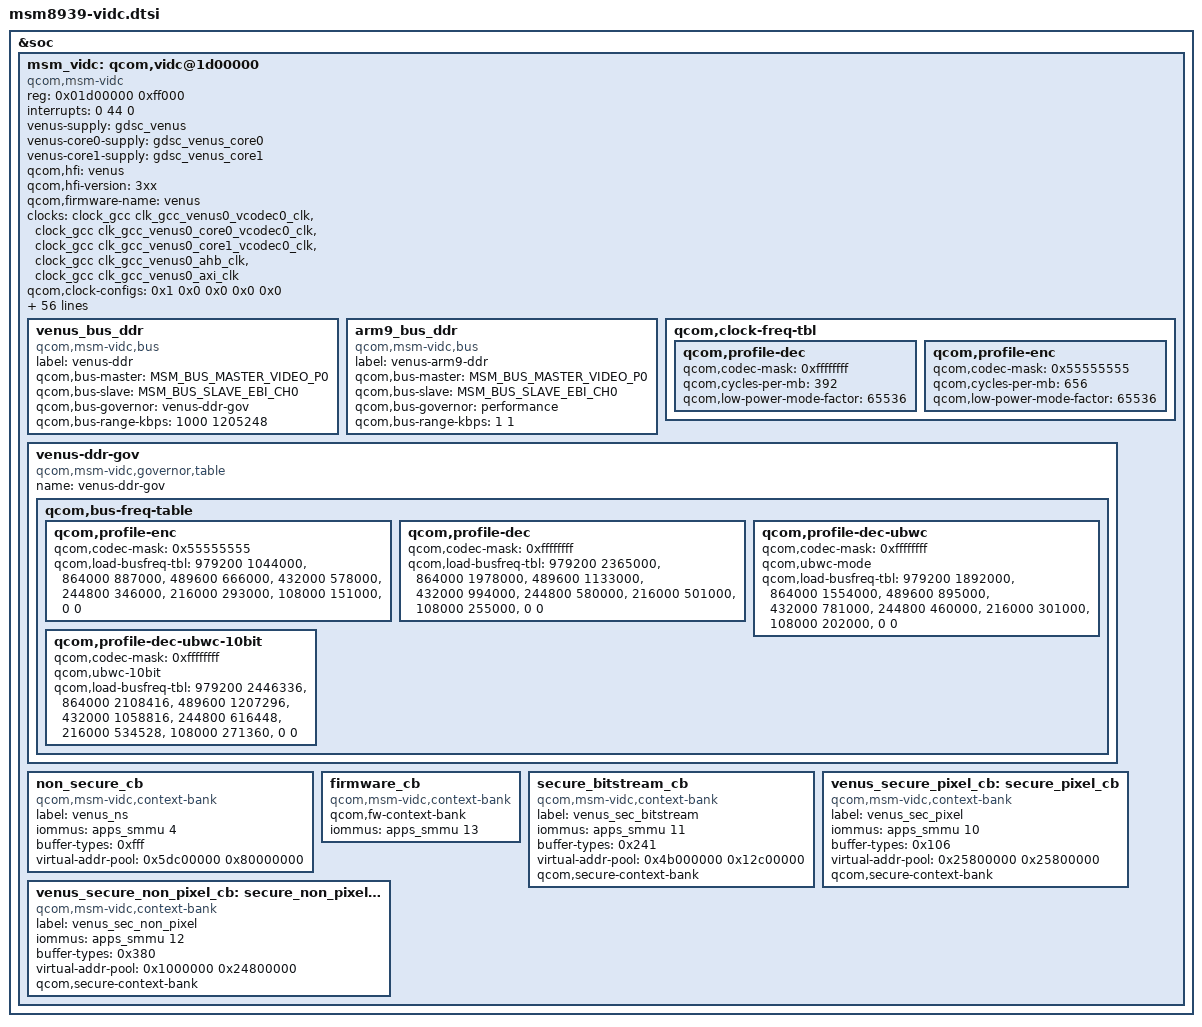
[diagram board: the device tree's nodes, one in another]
/* Copyright (c) 2017, The Linux Foundation. All rights reserved.
 *
 * This program is free software; you can redistribute it and/or modify
 * it under the terms of the GNU General Public License version 2 and
 * only version 2 as published by the Free Software Foundation.
 *
 * This program is distributed in the hope that it will be useful,
 * but WITHOUT ANY WARRANTY; without even the implied warranty of
 * MERCHANTABILITY or FITNESS FOR A PARTICULAR PURPOSE.  See the
 * GNU General Public License for more details.
 */

#include <dt-bindings/interrupt-controller/arm-gic.h>

&soc {
	msm_vidc: qcom,vidc@1d00000 {
		compatible = "qcom,msm-vidc";
		reg = <0x01d00000 0xff000>;
		interrupts = <0 44 0>;
		
		venus-supply = <&gdsc_venus>;
		venus-core0-supply = <&gdsc_venus_core0>;
		venus-core1-supply = <&gdsc_venus_core1>;

		qcom,hfi = "venus";
		qcom,hfi-version = "3xx";
		qcom,firmware-name = "venus";

		clocks = <&clock_gcc clk_gcc_venus0_vcodec0_clk>,
			<&clock_gcc clk_gcc_venus0_core0_vcodec0_clk>,
			<&clock_gcc clk_gcc_venus0_core1_vcodec0_clk>,
			<&clock_gcc clk_gcc_venus0_ahb_clk>,
			<&clock_gcc clk_gcc_venus0_axi_clk>;
		clock-names = "core_clk", "core0_clk", "core1_clk", "iface_clk", "bus_clk";

		qcom,clock-configs = <0x1 0x0 0x0 0x0 0x0>;
		qcom,allowed-clock-rates = <266670000 200000000 133330000>;
		qcom,slave-side-cp;
		qcom,sw-power-collapse;
		qcom,reset-clock-control;
		qcom,regulator-scaling;

		qcom,max-hw-load = <1011840>; /* 3840 x 2176 @ 30 fps + 3840 x 2176 @ 1 fps */
		qcom,dcvs-min-load = <734400>; /* 1920 x 1088 @ 90fps */
		qcom,dcvs-min-mbperframe = <32400>; /* 3840 x 2160 */

		qcom,load-freq-tbl =
			<979200 466000000 0x55555555>, /* TURBO, UHD30E   */
			<979200 400000000 0xffffffff>, /* NOM+ , UHD30D   */
			<734400 360000000 0xffffffff>, /* NOM  , 1080p90D */
			<734400 400000000 0x55555555>, /* NOM+ , 1080p90E */
			<489600 228570000 0xffffffff>, /* SVS  , 1080p60D */
			<489600 466000000 0x55555555>, /* TURBO, 1080p60E */
			<432000 228570000 0xffffffff>, /* SVS  , 720p120D */
			<432000 400000000 0x55555555>, /* NOM+ , 720p120E */
			<244800 133333333 0xffffffff>, /* SVS- , 1080p30D */
			<244800 228570000 0x55555555>, /* SVS  , 1080p30E */
			<216000 100000000 0xffffffff>, /* SVS- , 720p60D  */
			<216000 228570000 0x55555555>, /* SVS  , 720p60E  */
			<108000 80000000 0xffffffff>,  /* SVS--, 720p30D  */
			<108000 100000000 0x55555555>, /* SVS- , 720p30E  */
			<36000 72727200 0xffffffff>,   /* SVS--, 480p30D  */
			<36000 80000000 0x55555555>;   /* SVS--, 480p30E  */

		qcom,dcvs-tbl =
			/* Dec UHD@30 H.264, HEVC, VP8, VP9 - NOM to NOM+*/
			<816000 816000 979200 0x3f00000c>,

			/* Enc UHD@30 H.264/HEVC Turbo to Nom+ */
			<897600 821100 979200 0x4000004>,

			/* Enc True4K@24 H.264/HEVC Nom to Nom+ */
			<816000 720000 835584 0x4000004>;

		qcom,dcvs-limit =
			<32400 24>, /* Encoder UHD */
			<32400 24>; /* Decoder UHD */

		qcom,qdss-presets =
			<0x6025000 0x1000>,
			<0x6026000 0x1000>,
			<0x6021000 0x1000>,
			<0x6002000 0x1000>,
			<0x9180000 0x1000>,
			<0x9181000 0x1000>;

		qcom,reg-presets =
			<0xE0020 0x05555556>,
			<0xE0024 0x05555556>,
			<0x80124 0x00000003>;

		qcom,clock-voltage-tbl =
			<72727200 RPM_SMD_REGULATOR_LEVEL_SVS>,
			<80000000 RPM_SMD_REGULATOR_LEVEL_SVS>,
			<100000000 RPM_SMD_REGULATOR_LEVEL_SVS>,
			<133333333 RPM_SMD_REGULATOR_LEVEL_SVS>,
			<228570000 RPM_SMD_REGULATOR_LEVEL_SVS>,
			<310667000 RPM_SMD_REGULATOR_LEVEL_SVS_PLUS>,
			<360000000 RPM_SMD_REGULATOR_LEVEL_NOM>,
			<400000000 RPM_SMD_REGULATOR_LEVEL_NOM_PLUS>,
			<466000000 RPM_SMD_REGULATOR_LEVEL_TURBO>;

		qcom,vp9d-clock-voltage-tbl =
			<72727200 RPM_SMD_REGULATOR_LEVEL_SVS>,
			<80000000 RPM_SMD_REGULATOR_LEVEL_SVS>,
			<100000000 RPM_SMD_REGULATOR_LEVEL_SVS>,
			<133333333 RPM_SMD_REGULATOR_LEVEL_SVS>,
			<228570000 RPM_SMD_REGULATOR_LEVEL_SVS_PLUS>,
			<310667000 RPM_SMD_REGULATOR_LEVEL_NOM>,
			<360000000 RPM_SMD_REGULATOR_LEVEL_NOM_PLUS>,
			<400000000 RPM_SMD_REGULATOR_LEVEL_TURBO>;

		/* VIDC buses */
		venus_bus_ddr {
			compatible = "qcom,msm-vidc,bus";
			label = "venus-ddr";
			qcom,bus-master = <MSM_BUS_MASTER_VIDEO_P0>;
			qcom,bus-slave = <MSM_BUS_SLAVE_EBI_CH0>;
			qcom,bus-governor = "venus-ddr-gov";
			qcom,bus-range-kbps = <1000 1205248>;
		};

		arm9_bus_ddr {
			compatible = "qcom,msm-vidc,bus";
			label = "venus-arm9-ddr";
			qcom,bus-master = <MSM_BUS_MASTER_VIDEO_P0>;
			qcom,bus-slave = <MSM_BUS_SLAVE_EBI_CH0>;
			qcom,bus-governor = "performance";
			qcom,bus-range-kbps = <1 1>;
		};

		qcom,clock-freq-tbl {
			qcom,profile-dec {
				qcom,codec-mask = <0xffffffff>;
				qcom,cycles-per-mb = <392>;
				qcom,low-power-mode-factor = <65536>;
			};
			qcom,profile-enc {
				qcom,codec-mask = <0x55555555>;
				qcom,cycles-per-mb = <656>;
				qcom,low-power-mode-factor = <65536>;
			};
		};

		/* Bus governor tables */
		venus-ddr-gov {
			compatible = "qcom,msm-vidc,governor,table";
			name = "venus-ddr-gov";
			status = "ok";
			qcom,bus-freq-table {
				qcom,profile-enc {
					/* Codec mask for "all encoders" */
					qcom,codec-mask = <0x55555555>;
					qcom,load-busfreq-tbl =
						<979200 1044000>,  /* UHD30E     */
						<864000 887000>,   /* 720p240LPE */
						<489600 666000>,   /* 1080p60E   */
						<432000 578000>,   /* 720p120E   */
						<244800 346000>,   /* 1080p30E   */
						<216000 293000>,   /* 720p60E    */
						<108000 151000>,   /* 720p30E    */
						<0 0>;
				};
				qcom,profile-dec {
					/* Codec mask for "all encoders" */
					qcom,codec-mask = <0xffffffff>;
					qcom,load-busfreq-tbl =
						<979200 2365000>,  /* UHD30D     */
						<864000 1978000>,  /* 720p240D   */
						<489600 1133000>,  /* 1080p60D   */
						<432000 994000>,   /* 720p120D   */
						<244800 580000>,   /* 1080p30D   */
						<216000 501000>,   /* 720p60E    */
						<108000 255000>,   /* 720p30D    */
						<0 0>;
				};
				qcom,profile-dec-ubwc {
					qcom,codec-mask = <0xffffffff>;
					qcom,ubwc-mode;
					qcom,load-busfreq-tbl =
						<979200 1892000>,  /* UHD30D     */
						<864000 1554000>,  /* 720p240D   */
						<489600 895000>,   /* 1080p60D   */
						<432000 781000>,   /* 720p120D   */
						<244800 460000>,   /* 1080p30D   */
						<216000 301000>,   /* 720p60E    */
						<108000 202000>,   /* 720p30D    */
						<0 0>;
				};
				qcom,profile-dec-ubwc-10bit {
					qcom,codec-mask = <0xffffffff>;
					qcom,ubwc-10bit;
					qcom,load-busfreq-tbl =
						<979200 2446336>,  /* UHD30D     */
						<864000 2108416>,  /* 720p240D   */
						<489600 1207296>,  /* 1080p60D   */
						<432000 1058816>,  /* 720p120D   */
						<244800 616448>,   /* 1080p30D   */
						<216000 534528>,   /* 720p60D    */
						<108000 271360>,   /* 720p30D    */
						<0 0>;
				};
			};
		};
					
		/* IOMMU Contexts: Non Secure */
		/* Address pool from 1500MB to 3532MB && 3532MB to 3548MB */
		non_secure_cb {
			compatible = "qcom,msm-vidc,context-bank";
			label = "venus_ns";
			iommus = <&apps_smmu 4>;
			/* Buffer types relative to the two address pools */
			buffer-types = <0xfff>;
			virtual-addr-pool = <0x5dc00000 0x80000000>;
		};

		/* IOMMU Contexts: Secure */
		firmware_cb {
			compatible = "qcom,msm-vidc,context-bank";
			/* Firmware context bank is unlabeled in 4.4 */
			/* note: old-style label is "venus_fw" */
			qcom,fw-context-bank;
			iommus = <&apps_smmu 13>;
		};

		/* Address pool from 1200MB to 1500MB */
		secure_bitstream_cb {
			compatible = "qcom,msm-vidc,context-bank";
			label = "venus_sec_bitstream";
			iommus = <&apps_smmu 11>;
			buffer-types = <0x241>;
			virtual-addr-pool = <0x4b000000 0x12c00000>;
			qcom,secure-context-bank;
		};

		/* Address pool from 616MB to 1200MB */
		venus_secure_pixel_cb: secure_pixel_cb {
			compatible = "qcom,msm-vidc,context-bank";
			label = "venus_sec_pixel";
			iommus = <&apps_smmu 10>;
			buffer-types = <0x106>;
			virtual-addr-pool = <0x25800000 0x25800000>;
			qcom,secure-context-bank;
		};

		/* Address pool from 16MB to 616MB */
		venus_secure_non_pixel_cb: secure_non_pixel_cb {
			compatible = "qcom,msm-vidc,context-bank";
			label = "venus_sec_non_pixel";
			iommus = <&apps_smmu 12>;
			buffer-types = <0x380>;
			virtual-addr-pool = <0x1000000 0x24800000>;
			qcom,secure-context-bank;
		};
	};
};
